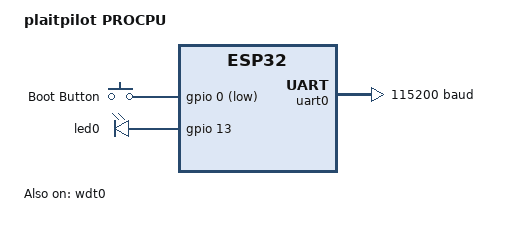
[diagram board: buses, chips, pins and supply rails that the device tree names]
/dts-v1/;

#include "espressif/esp32/esp32_wroom_32ue_n4.dtsi"
#include "plaitpilot_pinctrl.dtsi"
// this is standard input codes like for a keyboard, mouse, joystick etc. - the purpose is for convenience
// you can always use these zephyr specific input macros in source code as long as you define them in this dts file, this way only the dts file changes and the source code does not
#include <zephyr/dt-bindings/input/input-event-codes.h>
// this is the SoC configuration (partitions like boot, appcpu, procpu, sys, storage, coredump)
#include <espressif/partitions_0x0_amp.dtsi>

/ {
    model = "plaitpilot PROCPU";
    compatible = "custom,plaitpilot";

    aliases {
        //driver code uses this to keep procesors alive during code execution
        watchdog0 = &wdt0;
        // this is an LED that is "permenantly" soldered on the board
        led0 = &led0;
        uart-0 = &uart0;
        sw0 = &button0;
    };

    // this determines which hardware instances you want to use for core system level functions
    chosen {
        zephyr,sram = &sram0;
        zephyr,console = &uart0;
        zephyr,shell-uart = &uart0;
        zephyr,flash = &flash0;
        zephyr,code-partition = &slot0_partition;
    };

    buttons {
        compatible = "gpio-keys";
        button0: button_0 {
            gpios = <&gpio 0 (GPIO_PULL_UP | GPIO_ACTIVE_LOW)>;
            label = "Boot Button";
            zephyr,code = <INPUT_KEY_0>;
        };
    };

    led {
        compatible = "gpio-leds";
        // this is SPI MOSI for plaitpliot, this is just for a blinky demo
        led0: d13 {
            gpios = <&gpio 13 GPIO_ACTIVE_HIGH>;
        };
    };
};

&uart0 {
    status = "okay";
    current-speed = <115200>;
    pinctrl-0 = <&uart0_default>;
    pinctrl-names = "default";
};

&gpio0 {
    status = "okay";
};

&wdt0 {
    status = "okay";
};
